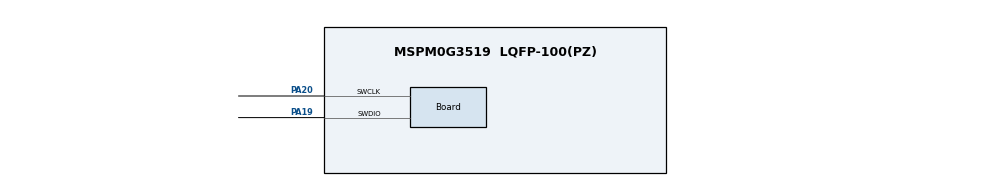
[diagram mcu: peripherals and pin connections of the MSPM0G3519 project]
/**
 * These arguments were used when this file was generated. They will be automatically applied on subsequent loads
 * via the GUI or CLI. Run CLI with '--help' for additional information on how to override these arguments.
 */
//@cliArgs --device "MSPM0G351X" --package "LQFP-100(PZ)" --part "Default"
//@v2CliArgs --device "MSPM0G3519" --package "LQFP-100(PZ)"
// @cliArgs --board /ti/boards/LP_MSPM0G3519 --rtos nortos

/**
 * Import the modules used in this configuration.
 */
const SYSCTL = scripting.addModule("/ti/driverlib/SYSCTL");
const GPIO   = scripting.addModule("/ti/driverlib/GPIO", {}, false);
const GPIO1  = GPIO.addInstance();
const GPIO2  = GPIO.addInstance();

/**
 * Write custom configuration values to the imported modules.
 */
SYSCTL.forceDefaultClkConfig = true;
SYSCTL.clockTreeEn           = true;

GPIO1.$name                          = "GPIO_LEDS";
GPIO1.port                           = "PORTB";
GPIO1.portSegment                    = "Lower";
GPIO1.associatedPins.create(1);
GPIO1.associatedPins[0].$name        = "STATUS_LED";
GPIO1.associatedPins[0].direction    = "OUTPUT";
GPIO1.associatedPins[0].initialValue = "SET";
GPIO1.associatedPins[0].assignedPin  = "6";

GPIO2.$name                          = "GPIO_BUZZER";
GPIO2.port                           = "PORTA";
GPIO2.portSegment                    = "Lower";
GPIO2.associatedPins.create(1);
GPIO2.associatedPins[0].$name        = "BUZZER";
GPIO2.associatedPins[0].direction    = "OUTPUT";
GPIO2.associatedPins[0].initialValue = "CLEARED";
GPIO2.associatedPins[0].assignedPin  = "12";

const Board                       = scripting.addModule("/ti/driverlib/Board", {}, false);
Board.peripheral.$assign          = "DEBUGSS";
Board.peripheral.swclkPin.$assign = "PA20";
Board.peripheral.swdioPin.$assign = "PA19";

const ProjectConfig              = scripting.addModule("/ti/project_config/ProjectConfig", {}, false);
ProjectConfig.migrationCondition = true;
